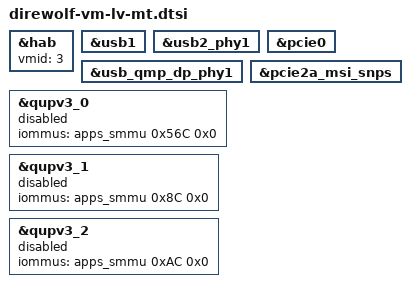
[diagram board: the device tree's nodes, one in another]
&hab {
	vmid = <3>;
};

&usb1 {
	status = "okay";
};

&usb2_phy1 {
	status = "okay";
};

&usb_qmp_dp_phy1 {
	status = "okay";
};

&pcie0 {
	status = "okay";
};

&pcie2a_msi_snps {
	status = "okay";
};

&qupv3_0 {
	iommus = <&apps_smmu 0x56C 0x0>;
	status = "disabled";
};

&qupv3_1 {
	iommus = <&apps_smmu 0x8C 0x0>;
	status = "disabled";
};

&qupv3_2 {
	iommus = <&apps_smmu 0xAC 0x0>;
	status = "disabled";
};
